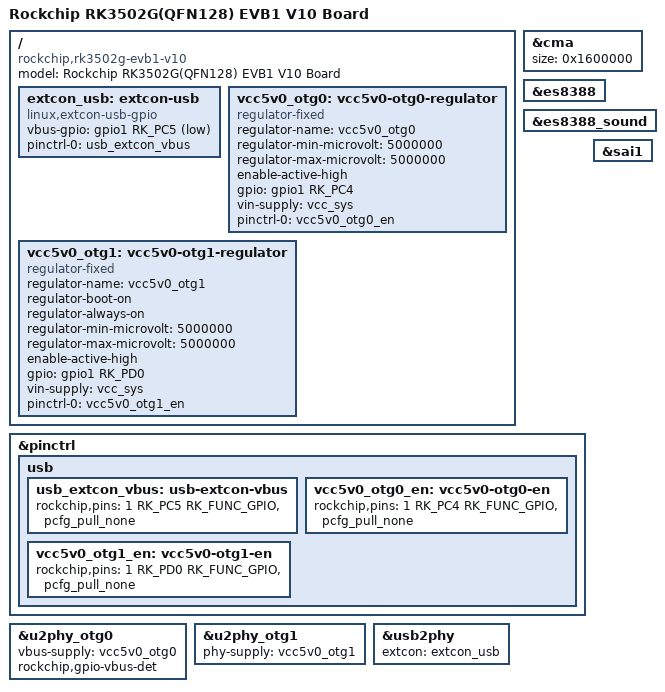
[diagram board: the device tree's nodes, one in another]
// SPDX-License-Identifier: (GPL-2.0+ OR MIT)
/*
 * Copyright (c) 2024 Rockchip Electronics Co., Ltd.
 */

/dts-v1/;

#include "rk3502.dtsi"
#include "rk3502-evb1-v10.dtsi"

/ {
	model = "Rockchip RK3502G(QFN128) EVB1 V10 Board";
	compatible = "rockchip,rk3502g-evb1-v10", "rockchip,rk3502";

	extcon_usb: extcon-usb {
		compatible = "linux,extcon-usb-gpio";
		vbus-gpio = <&gpio1 RK_PC5 GPIO_ACTIVE_LOW>;
		pinctrl-names = "default";
		pinctrl-0 = <&usb_extcon_vbus>;
		status = "okay";
	};

	vcc5v0_otg0: vcc5v0-otg0-regulator {
		compatible = "regulator-fixed";
		regulator-name = "vcc5v0_otg0";
		regulator-min-microvolt = <5000000>;
		regulator-max-microvolt = <5000000>;
		enable-active-high;
		gpio = <&gpio1 RK_PC4 GPIO_ACTIVE_HIGH>;
		vin-supply = <&vcc_sys>;
		pinctrl-names = "default";
		pinctrl-0 = <&vcc5v0_otg0_en>;
	};

	vcc5v0_otg1: vcc5v0-otg1-regulator {
		compatible = "regulator-fixed";
		regulator-name = "vcc5v0_otg1";
		regulator-boot-on;
		regulator-always-on;
		regulator-min-microvolt = <5000000>;
		regulator-max-microvolt = <5000000>;
		enable-active-high;
		gpio = <&gpio1 RK_PD0 GPIO_ACTIVE_HIGH>;
		vin-supply = <&vcc_sys>;
		pinctrl-names = "default";
		pinctrl-0 = <&vcc5v0_otg1_en>;
	};
};

&cma {
	size = <0x1600000>;
};

&es8388 {
	status = "okay";
};

&es8388_sound {
	status = "okay";
};

&pinctrl {
	usb {
		usb_extcon_vbus: usb-extcon-vbus {
			rockchip,pins = <1 RK_PC5 RK_FUNC_GPIO &pcfg_pull_none>;
		};

		vcc5v0_otg0_en: vcc5v0-otg0-en {
			rockchip,pins = <1 RK_PC4 RK_FUNC_GPIO &pcfg_pull_none>;
		};

		vcc5v0_otg1_en: vcc5v0-otg1-en {
			rockchip,pins = <1 RK_PD0 RK_FUNC_GPIO &pcfg_pull_none>;
		};
	};
};

&sai1 {
	status = "okay";
};

&u2phy_otg0 {
	vbus-supply = <&vcc5v0_otg0>;
	rockchip,gpio-vbus-det;
	status = "okay";
};

&u2phy_otg1 {
	phy-supply = <&vcc5v0_otg1>;
	status = "okay";
};

&usb2phy {
	extcon = <&extcon_usb>;
	status = "okay";
};
